# SPC1169 register map
File version: 2022071043481212
CPU: cm4 r1p0, little endian, no MPU, FPU, 4 interrupt priority bits
Registers are 32-bit, read-write, reset 0x0 unless marked. A register's access mark holds for its fields unless they carry their own. Offsets are from the block's base; [hi:lo] are bit positions; {n}, {i} and the like mark numbered series; 'fields as' and 'values as' point back to an identical list.

## FLASHC
Base 0x40001B00
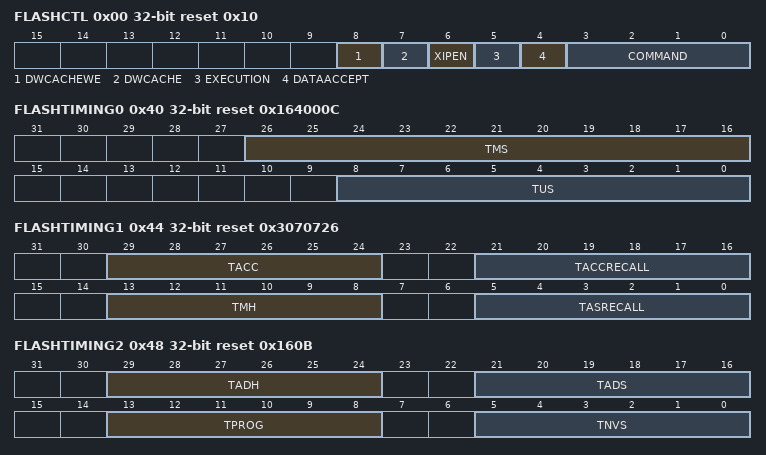
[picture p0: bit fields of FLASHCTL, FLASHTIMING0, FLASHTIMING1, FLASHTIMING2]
0x00 FLASHCTL reset 0x10 — Flash Control Register
  [8] DWCACHEWE — DWCACHE bit write enable. Need to write as 1 at the same time when writing DWCACHE bit
    0=NO_EFFECT (Write 0 has no effect and always reads back 0); 1=ENABLE (Write 1 enables concurrent write to DWCACHE. This bit is self-cleared to 0)
  [7] DWCACHE — Enable simple cache if the new address are in the same double-word as the last address
    0=DISABLE (Disable double-word cache); 1=ENABLE (Enable double-word cache)
  [6] XIPEN — XIP module enable
    0=DISABLE (Disable XIP module); 1=ENABLE (Enable XIP module)
  [5] EXECUTION — Command is in execution
    0=IDLE (Write a 0 has no effect. Read a 0 indicates no command execution); 1=EXECUTION (Write a 1 starts a new command execution cycle. Read a 1 indicates command is still executing. It will change to 0 after execution is accomplished.)
  [4] DATAACCEPT ro — FLASHDIN cannot be changed when this bit is 0
  [3:0] COMMAND — Flash command
    0=POWER_UP; 1=READ; 2=PROG_WORD (Program word); 3=PROG_PAGE (Program page); 4=ERASE_SECTOR; 5=ERASE_CHIP; 6=RECALL_READ; 7=SET_CONFIG (Set configuration); 14=VERIFY_READ; 15=POWER_DOWN (Powe down)
0x08 FLASHADDR — Flash Address Register
  [31:0] ADDR — Flash address
0x10 FLASHDINL — Flash Data Input Low Word Register
  [31:0] DINL — Flash input low word data
0x14 FLASHDINH — Flash Data Input High Word Register
  [31:0] DINH — Flash input high word data
0x18 FLASHDINE — Flash Data Input ECC Byte Register
  [7:0] DINE — Flash input ECC byte data. It is only effective when hardware ECC is disabled
0x1C FLASHDINP — Flash Data Input Pattern Register
  [2:0] PATTERN — Flash raw input pattern without ECC correction
    0=NONE (Input is set by FLASHDIN{E|H|L}); 4=ALL0 (All 0's); 5=CB01 (All 0x55 checkboard bytes); 6=CB10 (All 0xAA checkboard bytes); 7=ALL1 (All 1's)
0x20 FLASHDOUTL ro — Flash Data Output Low Word Register
  [31:0] DOUTL — Flash output low word data
0x24 FLASHDOUTH ro — Flash Data Output High Word Register
  [31:0] DOUTH — Flash output high word data
0x28 FLASHDOUTE ro — Flash Data Output ECC Byte Register
  [7:0] DOUTE — Flash output ECC byte data
0x2C FLASHDOUTP ro — Flash Data Output Pattern Register
  [2:0] PATTERN — Flash raw output pattern without ECC correction
    0=NONE (No special pattern recognied); 4=ALL0 (All 0's); 5=CB01 (All 0x55 checkboard bytes); 6=CB10 (All 0xAA checkboard bytes); 7=ALL1 (All 1's)
0x40 FLASHTIMING0 reset 0x164000C — Flash Timing Register 0
  [26:16] TMS, [8:0] TUS
0x44 FLASHTIMING1 reset 0x3070726 — Flash Timing Register 1
  [29:24] TACC, [21:16] TACCRECALL, [13:8] TMH, [5:0] TASRECALL
0x48 FLASHTIMING2 reset 0x160B — Flash Timing Register 2
  [29:24] TADH, [21:16] TADS, [13:8] TPROG, [5:0] TNVS
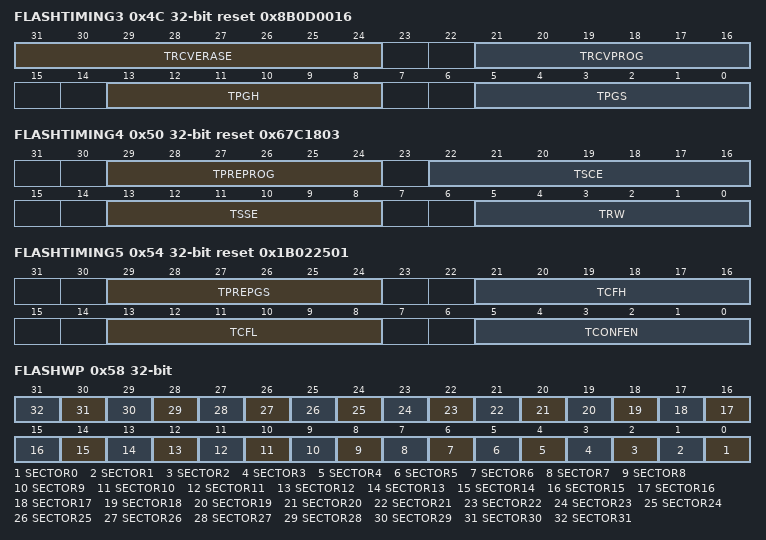
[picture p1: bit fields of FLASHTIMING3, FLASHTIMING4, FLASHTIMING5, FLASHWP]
0x4C FLASHTIMING3 reset 0x8B0D0016 — Flash Timing Register 3
  [31:24] TRCVERASE, [21:16] TRCVPROG, [13:8] TPGH, [5:0] TPGS
0x50 FLASHTIMING4 reset 0x67C1803 — Flash Timing Register 4
  [29:24] TPREPROG, [22:16] TSCE, [13:8] TSSE, [5:0] TRW
0x54 FLASHTIMING5 reset 0x1B022501 — Flash Timing Register 5
  [29:24] TPREPGS, [21:16] TCFH, [13:8] TCFL, [5:0] TCONFEN
0x58 FLASHWP — Flash Write Protect Register
  [all] fields
    0=UNPROTECT (Can be programed or erased); 1=PROTECT (Cannot be programed or sector erased)
  [n] SECTOR{n} (n=0..31) — Write protection for flash sector {n}
0x60 FLASHCREGKEY — Flash Controller Register Write-Allow Key Register
  [31:0] KEY — Write 0x1ACCE551 to unlock protected flash registers

## PGA
Base 0x40003000
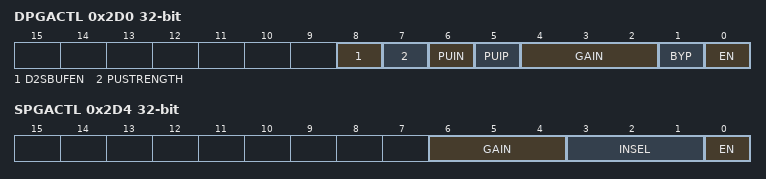
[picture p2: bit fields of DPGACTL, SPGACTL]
0x2D0 DPGACTL — Differential PGA Control Register
  [8] D2SBUFEN — PGA differential to single-ended buffer enable
    0=DISABLE; 1=ENABLE
  [7] PUSTRENGTH — PGA pull-up strength
    0=2_MA; 1=10_MA
  [6] PUIN — PGA negative input pull-up enable
    0=DISABLE (Do not pull-up); 1=ENABLE (Pull-up)
  [5] PUIP — PGA positive input pull-up enable
    0=DISABLE (Do not pull-up); 1=ENABLE (Pull-up)
  [4:2] GAIN — PGA differential gain
    0=2X; 1=4X; 2=8X; 3=16X; 4=24X; 5=32X; 6=48X; 7=64X
  [1] BYP — PGA bypass
    0=DISABLE (Not bypass); 1=ENABLE (Bypass)
  [0] EN — PGA enable
    0=DISABLE (Disable DPGA); 1=ENABLE (Enable DPGA)
0x2D4 SPGACTL — Single-ended PGA Control Register
  [6:4] GAIN — PGA gain
    0=1X; 1=2X; 2=4X; 3=8X; 4=16X; 5=32X; 6=48X; 7=64X
  [3:1] INSEL — PGA input select
    {v}=ANA_IN{v} (v=0..4); 5=TSENS_N (T-sensor negative output); 6=TSENS_P (T-sensor positive output); 7=ATEST (ATEST output)
  [0] EN — PGA enable
    0=DISABLE (Disable SPGA); 1=ENABLE (Enable SPGA)
0x2F0 PGAREGKEY reset 0x1ACCE551 — PGA Register Write-Allow Key Register
  [31:0] KEY — Write 0x1ACCE551 to unlock protected PGA registers

## CANMBOX0
Base 0x40004000
Same registers: CANMBOX{n} {0x40004000+0x50*n} (n=1..63)
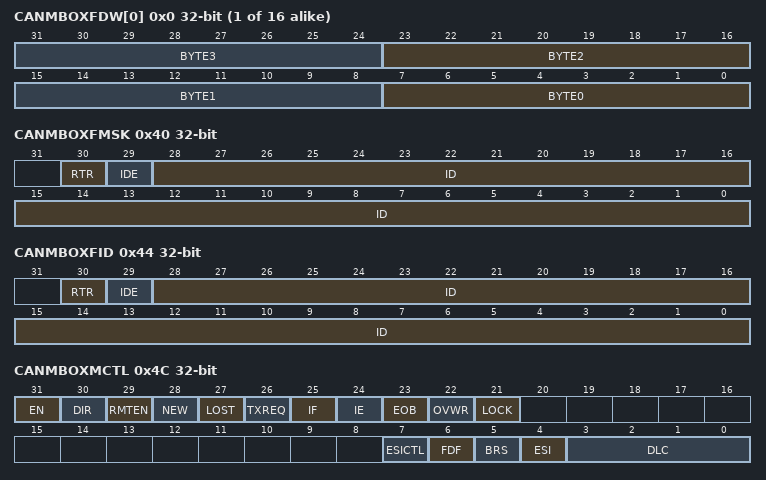
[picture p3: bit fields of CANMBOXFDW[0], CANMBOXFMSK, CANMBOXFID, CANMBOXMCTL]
{0x0+4i} CANMBOXFDW[{i}] (i=0..15) — Mailbox Data Word Register
  [8n+7:8n] BYTE{n} (n=0..3) — Byte (4 * N + {n}) of CAN frame, N is CANMBOXFDW index.
0x40 CANMBOXFMSK — Mailbox Frame Mask Register
  [30] RTR — Remote transmission request bit mask.
    0=DONT_CARE (This bit in the message identifier is not used for acceptance filtering (don't care).); 1=CARE (This bit in the message identifier is used for acceptance filtering.)
  [29] IDE — Identifier extension bit mask.
    values as RTR
  [28:0] ID — Identifier mask.
0x44 CANMBOXFID — Mailbox Frame Identifier Register
  [30] RTR — Remote transmission request bit.
    0=DATA (Message is data frame.); 1=REMOTE (Message is remote frame.)
  [29] IDE — Identifier extension bit.
    0=STANDARD (Message is standard CAN frame.); 1=EXTENDED (Message is extended CAN frame.)
  [28:0] ID — Identifier.
0x48 CANMBOXMTS — Mailbox Message Timestamp Register. Note: Read only.
  [31:0] TS — Timestamp
0x4C CANMBOXMCTL — Mailbox Message Control Register
  [31] EN — Enable mailbox
    0=DISABLE; 1=ENABLE
  [30] DIR — Message data transfer direction on bus.
    0=RECEPTION (Wait receive data.); 1=TRANSMISSION (Wait transmit data.)
  [29] RMTEN — Enable remote frame auto response.
    0=DISABLE; 1=ENABLE (DIR==0: transmit remote frame first, then wait receive data frame. DIR==1: wait receive remote frame first, then transmit message in mailbox.)
  [28] NEW — New message.
    0=OLD; 1=NEW
  [27] LOST — Received message lost. Note: always write 0 to this field.
    0=NOT_OCCURED; 1=OCCURRED (For reception: old message lost. For transmission: data error occurred during transmission, MBCTL.EN will be cleared for this reason.)
  [26] TXREQ — Transmit request.
    0=DISABLE; 1=ENABLE
  [25] IF — Interrupt pending flag. Note: always write 0 to this field.
    0=NOT_OCCURED; 1=OCCURRED
  [24] IE — Enable mailbox transfer interrupt.
    0=DISABLE; 1=ENABLE
  [23] EOB — End of block.
    0=DISABLE; 1=ENABLE
  [22] OVWR — Enable overWrite mailbox which is end of block.
    0=DISABLE; 1=ENABLE
  [21] LOCK — Milbox locked flag. Note: always write 0 to this field.
    0=NOT_OCCURED; 1=OCCURRED
  [7] ESICTL — Control send error state indicator enable
    0=DISABLE (Send ESI value equal node passive state, node active send dominant bit and passive send recessive bit.); 1=ENABLE (Send ESI valud by MBFCTL.ESI.)
  [6] FDF — FD format indicator.
    0=DISABLE; 1=ENABLE
  [5] BRS — Bit rate switch.
    0=DISABLE; 1=ENABLE
  [4] ESI — Error state indicator.
    0=ACTIVE; 1=PASSIVE
  [3:0] DLC — Data length code.
    0=0-byte; 1=1-byte; {v}={v}-bytes (v=2..8); 9=12-bytes, valid for CANFD only. If set for CAN format, DLC force to 8-bytes.; 10=16-bytes, valid for CANFD only. If set for CAN format, DLC force to 8-bytes.; 11=20-bytes, valid for CANFD only. If set for CAN format, DLC force to 8-bytes.; 12=24-bytes, valid for CANFD only. If set for CAN format, DLC force to 8-bytes.; 13=32-bytes, valid for CANFD only. If set for CAN format, DLC force to 8-bytes.; 14=48-bytes, valid for CANFD only. If set for CAN format, DLC force to 8-bytes.; 15=64-bytes, valid for CANFD only. If set for CAN format, DLC force to 8-bytes.
